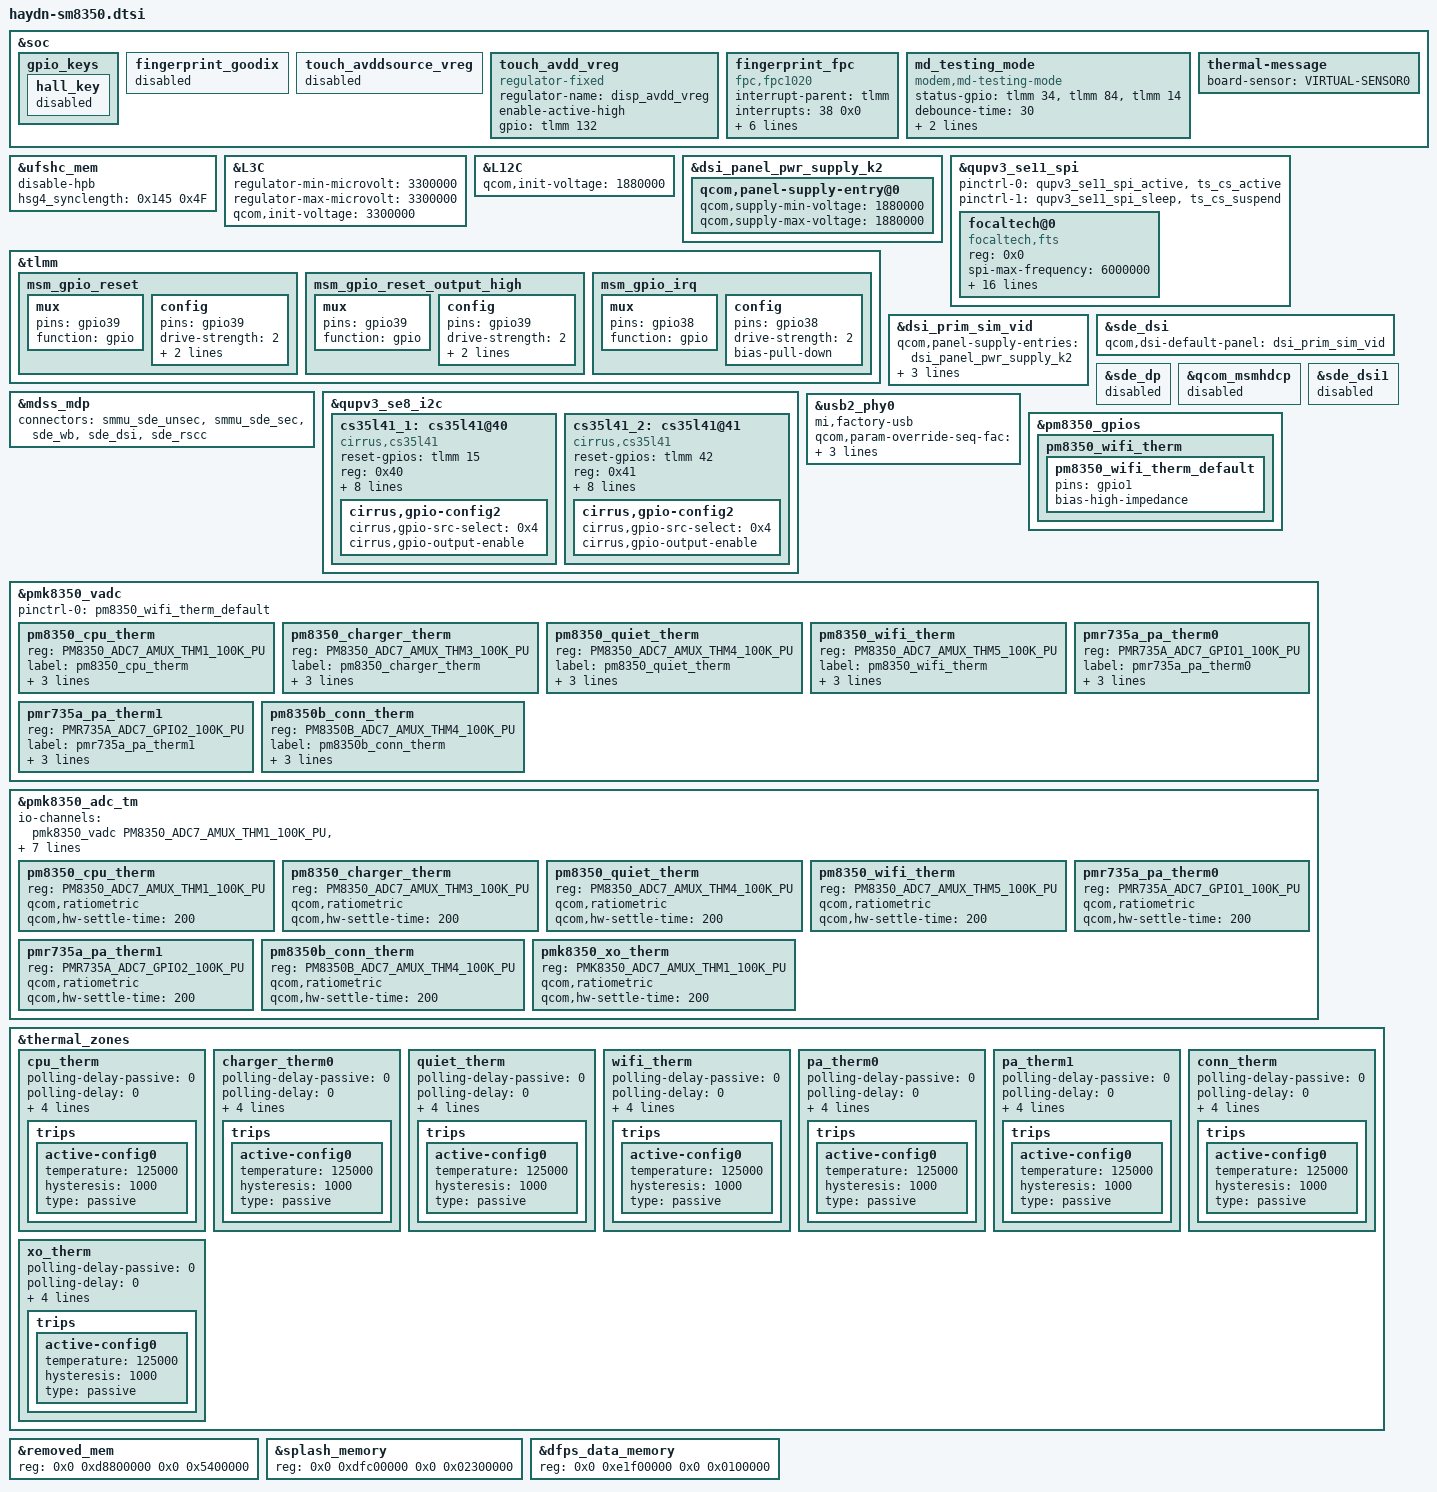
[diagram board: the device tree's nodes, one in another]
/*
this file is for attribution only of star
And public attribution of xiaomi platforms(like venus and so and)
*/

#include "haydn-pinctrl.dtsi"
#include "xiaomi-sm8350-common.dtsi"
#include "haydn-audio-overlay.dtsi"
#include "camera/haydn-sm8350-camera-sensor.dtsi"

&soc {
	gpio_keys {
		hall_key {
			status = "disable";
		};
	};
	fingerprint_goodix {
		status = "disable";
	};

	touch_avddsource_vreg {
		status = "disable";
	};

	touch_avdd_vreg: touch_avdd_vreg {
		compatible = "regulator-fixed";
		regulator-name = "disp_avdd_vreg";
		enable-active-high;
		gpio = <&tlmm 132 0>;
	};

	fingerprint_fpc {
		status = "ok";
		compatible = "fpc,fpc1020";
		interrupt-parent = <&tlmm>;
		interrupts = <38 0x0>;
		fpc,gpio_rst    = <&tlmm 39 0x0>;
		fpc,gpio_irq    = <&tlmm 38 0x0>;
		fp_vdd_vreg-supply = <&L3C>;
		pinctrl-names = "fpc1020_reset_reset",
						"fpc1020_reset_active",
						"fpc1020_irq_active";

		pinctrl-0 = <&msm_gpio_reset>;
		pinctrl-1 = <&msm_gpio_reset_output_high>;
		pinctrl-2 = <&msm_gpio_irq>;
	};

	md_testing_mode {
		compatible = "modem,md-testing-mode";
		status-gpio = <&tlmm 34 0x00>,
                      <&tlmm 84 0x00>,
					  <&tlmm 14 0x00>;
		debounce-time = <30>;
		pinctrl-names = "default";
		pinctrl-0 = <&ant1_ctrl_irq &ant3_ctrl_irq &ant8_ctrl_irq>;
	};
};

&ufshc_mem {
	disable-hpb;

	hsg4_synclength = /bits/ 16 <0x145 0x4F>;

	status = "ok";
};


&L3C {
	regulator-min-microvolt = <3300000>;
	regulator-max-microvolt = <3300000>;
	qcom,init-voltage = <3300000>;
};
&L12C {
	qcom,init-voltage = <1880000>;
};

&dsi_panel_pwr_supply_k2 {
	qcom,panel-supply-entry@0 {
		qcom,supply-min-voltage = <1880000>;
		qcom,supply-max-voltage = <1880000>;
	};
};

&tlmm {
		/* FP_RESET_N */
	msm_gpio_reset: msm_gpio_reset {
		mux {
			pins = "gpio39";
			function = "gpio";
		};
		config {
			pins = "gpio39";
			drive-strength = <2>;
			bias-disable;
			output-low;
		};
	};
		/* FP_RESET_N, state device active*/
	msm_gpio_reset_output_high: msm_gpio_reset_output_high {
		mux {
			pins = "gpio39";
			function = "gpio";
		};
		config {
			pins = "gpio39";
			drive-strength = <2>;
			bias-disable;
			output-high;
		};
	};
		/* FP_INT_N */
	msm_gpio_irq: msm_gpio_irq {
		mux {
			pins = "gpio38";
			function = "gpio";
		};
		config {
			pins = "gpio38";
			drive-strength = <2>;
			bias-pull-down;
		};
	};
};

&qupv3_se11_spi {
	status = "ok";
	pinctrl-0 = <&qupv3_se11_spi_active &ts_cs_active>;
	pinctrl-1 = <&qupv3_se11_spi_sleep &ts_cs_suspend>;
	focaltech@0 {
		status = "ok";
		compatible = "focaltech,fts";
		reg = <0x0>;
		spi-max-frequency = <6000000>;
		interrupt-parent = <&tlmm>;
		interrupts = <23 0x2008>;
		pinctrl-names = "pmx_ts_active", "pmx_ts_suspend", "pmx_ts_release";
		pinctrl-0 = <&mi_ts_active>;
		pinctrl-1 = <&ts_int_suspend &ts_reset_suspend>;
		pinctrl-2 = <&ts_release>;
		vdd-supply = <&touch_avdd_vreg>;
		vcc_i2c-supply = <&L2C>;
		focaltech,reset-gpio = <&tlmm 22 0x00>;
		focaltech,irq-gpio = <&tlmm 23 0x2008>;
		focaltech,max-touch-number = <10>;
		focaltech,display-coords = <0 0 8640 19200>;
		focaltech,open-min = <3000>;
		focaltech,touch-range-array = <1 5 10 15 20>;
		focaltech,touch-def-array = <3 3 3 3>;
		focaltech,touch-expert-array = <10 10 10 10
						20 20 15 10
						20 20 20 10>;
	};
};

&dsi_prim_sim_vid {
       qcom,panel-supply-entries = <&dsi_panel_pwr_supply_k2>;
       qcom,mdss-dsi-bl-pmic-control-type = "bl_ctrl_dcs";
       qcom,platform-reset-gpio = <&tlmm 24 0>;
};

&sde_dsi {
       qcom,dsi-default-panel = <&dsi_prim_sim_vid>;
};

&sde_dp {
	status = "disabled";
};

&qcom_msmhdcp {
	status = "disabled";
};

&sde_dsi1 {
	status = "disabled";
};

&mdss_mdp {
	connectors = <&smmu_sde_unsec &smmu_sde_sec &sde_wb &sde_dsi
		&sde_rscc>;
};

&qupv3_se8_i2c {
	status = "ok";
	cs35l41_1: cs35l41@40 {
		status = "ok";
		compatible = "cirrus,cs35l41";
		reset-gpios = <&tlmm 15 0>;
		reg = <0x40>;
		interrupt-parent = <&tlmm>;
		interrupts = <44 8>;
		cirrus,temp-warn_threshold = <3>;
		cirrus,boost-peak-milliamp = <4000>;
		cirrus,boost-ind-nanohenry = <1000>;
		cirrus,boost-cap-microfarad = <15>;
		cirrus,asp-sdout-hiz = <3>;
		sound-name-prefix = "RCV";
		cirrus,gpio-config2 {
			cirrus,gpio-src-select = <0x4>;
			cirrus,gpio-output-enable;
		};
	};
	cs35l41_2: cs35l41@41 {
		compatible = "cirrus,cs35l41";
		reset-gpios = <&tlmm 42 0>;
		reg = <0x41>;
		interrupt-parent = <&tlmm>;
		interrupts = <79 8>;
		cirrus,temp-warn_threshold = <3>;
		cirrus,boost-peak-milliamp = <4000>;
		cirrus,boost-ind-nanohenry = <1000>;
		cirrus,boost-cap-microfarad = <15>;
		cirrus,asp-sdout-hiz = <3>;
		cirrus,right-channel-amp;
		cirrus,gpio-config2 {
			cirrus,gpio-src-select = <0x4>;
			cirrus,gpio-output-enable;
		};
	};
};

&usb2_phy0 {
        mi,factory-usb;
        qcom,param-override-seq-fac =
        <0xc6 0x6c      /* override_x0 */
         0x0e 0x70      /* override_x1 */
         0x00 0x74>;    /* override x2 */
	qcom,param-override-seq =
        <0xc7 0x6c      /* override_x0 */
         0x0e 0x70      /* override_x1 */
         0x00 0x74>;    /* override x2 */
};

&pm8350_gpios {
	pm8350_wifi_therm {
		pm8350_wifi_therm_default: pm8350_wifi_therm_default {
			pins = "gpio1";
			bias-high-impedance;
		};
	};
};

&pmk8350_vadc {
	pinctrl-names = "default";
	pinctrl-0 = <&pm8350_wifi_therm_default>;

	pm8350_cpu_therm {
		reg = <PM8350_ADC7_AMUX_THM1_100K_PU>;
		label = "pm8350_cpu_therm";
		qcom,ratiometric;
		qcom,hw-settle-time = <200>;
		qcom,pre-scaling = <1 1>;
	};

	pm8350_charger_therm {
		reg = <PM8350_ADC7_AMUX_THM3_100K_PU>;
		label = "pm8350_charger_therm";
		qcom,ratiometric;
		qcom,hw-settle-time = <200>;
		qcom,pre-scaling = <1 1>;
	};

	pm8350_quiet_therm {
		reg = <PM8350_ADC7_AMUX_THM4_100K_PU>;
		label = "pm8350_quiet_therm";
		qcom,ratiometric;
		qcom,hw-settle-time = <200>;
		qcom,pre-scaling = <1 1>;
	};

	pm8350_wifi_therm {
		reg = <PM8350_ADC7_AMUX_THM5_100K_PU>;
		label = "pm8350_wifi_therm";
		qcom,ratiometric;
		qcom,hw-settle-time = <200>;
		qcom,pre-scaling = <1 1>;
	};

	pmr735a_pa_therm0 {
		reg = <PMR735A_ADC7_GPIO1_100K_PU>;
		label = "pmr735a_pa_therm0";
		qcom,ratiometric;
		qcom,hw-settle-time = <200>;
		qcom,pre-scaling = <1 1>;
	};

	pmr735a_pa_therm1 {
		reg = <PMR735A_ADC7_GPIO2_100K_PU>;
		label = "pmr735a_pa_therm1";
		qcom,ratiometric;
		qcom,hw-settle-time = <200>;
		qcom,pre-scaling = <1 1>;
	};

	pm8350b_conn_therm {
		reg = <PM8350B_ADC7_AMUX_THM4_100K_PU>;
		label = "pm8350b_conn_therm";
		qcom,ratiometric;
		qcom,hw-settle-time = <200>;
		qcom,pre-scaling = <1 1>;
	};
};

&pmk8350_adc_tm {
	io-channels = <&pmk8350_vadc PM8350_ADC7_AMUX_THM1_100K_PU>,	//cpu_therm
			<&pmk8350_vadc PM8350_ADC7_AMUX_THM3_100K_PU>,	//charger_therm0
			<&pmk8350_vadc PM8350_ADC7_AMUX_THM4_100K_PU>,	//quiet_therm
			<&pmk8350_vadc PM8350_ADC7_AMUX_THM5_100K_PU>,	//wifi_therm
			<&pmk8350_vadc PMR735A_ADC7_GPIO1_100K_PU>,	//pa_therm0
			<&pmk8350_vadc PMR735A_ADC7_GPIO2_100K_PU>,	//pa_therm1
			<&pmk8350_vadc PM8350B_ADC7_AMUX_THM4_100K_PU>,	//conn_therm
			<&pmk8350_vadc PMK8350_ADC7_AMUX_THM1_100K_PU>;	//xo_therm

	pm8350_cpu_therm {
		reg = <PM8350_ADC7_AMUX_THM1_100K_PU>;
		qcom,ratiometric;
		qcom,hw-settle-time = <200>;
	};

	pm8350_charger_therm {
		reg = <PM8350_ADC7_AMUX_THM3_100K_PU>;
		qcom,ratiometric;
		qcom,hw-settle-time = <200>;
	};

	pm8350_quiet_therm {
		reg = <PM8350_ADC7_AMUX_THM4_100K_PU>;
		qcom,ratiometric;
		qcom,hw-settle-time = <200>;
	};

	pm8350_wifi_therm {
		reg = <PM8350_ADC7_AMUX_THM5_100K_PU>;
		qcom,ratiometric;
		qcom,hw-settle-time = <200>;
	};

	pmr735a_pa_therm0 {
		reg = <PMR735A_ADC7_GPIO1_100K_PU>;
		qcom,ratiometric;
		qcom,hw-settle-time = <200>;
	};

	pmr735a_pa_therm1 {
		reg = <PMR735A_ADC7_GPIO2_100K_PU>;
		qcom,ratiometric;
		qcom,hw-settle-time = <200>;
	};

	pm8350b_conn_therm {
		reg = <PM8350B_ADC7_AMUX_THM4_100K_PU>;
		qcom,ratiometric;
		qcom,hw-settle-time = <200>;
	};

	pmk8350_xo_therm {
		reg = <PMK8350_ADC7_AMUX_THM1_100K_PU>;
		qcom,ratiometric;
		qcom,hw-settle-time = <200>;
	};
};

&thermal_zones {
        cpu_therm {
                polling-delay-passive = <0>;
                polling-delay = <0>;
                thermal-governor = "user_space";
                thermal-sensors = <&pmk8350_adc_tm PM8350_ADC7_AMUX_THM1_100K_PU>;
                wake-capable-sensor;
                trips {
                        active-config0 {
                                temperature = <125000>;
                                hysteresis = <1000>;
                                type = "passive";
                        };
                };
        };

        charger_therm0 {
                polling-delay-passive = <0>;
                polling-delay = <0>;
                thermal-governor = "user_space";
                thermal-sensors = <&pmk8350_adc_tm PM8350_ADC7_AMUX_THM3_100K_PU>;
                wake-capable-sensor;
                trips {
                        active-config0 {
                                temperature = <125000>;
                                hysteresis = <1000>;
                                type = "passive";
                        };
                };
        };

        quiet_therm {
                polling-delay-passive = <0>;
                polling-delay = <0>;
                thermal-governor = "user_space";
                thermal-sensors = <&pmk8350_adc_tm PM8350_ADC7_AMUX_THM4_100K_PU>;
                wake-capable-sensor;
                trips {
                        active-config0 {
                                temperature = <125000>;
                                hysteresis = <1000>;
                                type = "passive";
                        };
                };
        };

        wifi_therm {
                polling-delay-passive = <0>;
                polling-delay = <0>;
                thermal-governor = "user_space";
                thermal-sensors = <&pmk8350_adc_tm PM8350_ADC7_AMUX_THM5_100K_PU>;
                wake-capable-sensor;
                trips {
                        active-config0 {
                                temperature = <125000>;
                                hysteresis = <1000>;
                                type = "passive";
                        };
                };
        };

        pa_therm0 {
                polling-delay-passive = <0>;
                polling-delay = <0>;
                thermal-governor = "user_space";
                thermal-sensors = <&pmk8350_adc_tm PMR735A_ADC7_GPIO1_100K_PU>;
                wake-capable-sensor;
                trips {
                        active-config0 {
                                temperature = <125000>;
                                hysteresis = <1000>;
                                type = "passive";
                        };
                };
        };

        pa_therm1 {
                polling-delay-passive = <0>;
                polling-delay = <0>;
                thermal-governor = "user_space";
                thermal-sensors = <&pmk8350_adc_tm PMR735A_ADC7_GPIO2_100K_PU>;
                wake-capable-sensor;
                trips {
                        active-config0 {
                                temperature = <125000>;
                                hysteresis = <1000>;
                                type = "passive";
                        };
                };
        };

	conn_therm {
		polling-delay-passive = <0>;
		polling-delay = <0>;
		thermal-governor = "user_space";
		thermal-sensors = <&pmk8350_adc_tm PM8350B_ADC7_AMUX_THM4_100K_PU>;
		wake-capable-sensor;
		trips {
			active-config0 {
				temperature = <125000>;
				hysteresis = <1000>;
				type = "passive";
			};
		};
	};

	xo_therm {
		polling-delay-passive = <0>;
		polling-delay = <0>;
		thermal-governor = "user_space";
		thermal-sensors = <&pmk8350_adc_tm PMK8350_ADC7_AMUX_THM1_100K_PU>;
		wake-capable-sensor;
		trips {
			active-config0 {
				temperature = <125000>;
				hysteresis = <1000>;
				type = "passive";
			};
		};
	};
};

&soc {
	thermal-message {
		board-sensor = "VIRTUAL-SENSOR0";
	};
};

&removed_mem {
	reg = <0x0 0xd8800000 0x0 0x5400000>;
};

&splash_memory {
	reg = <0x0 0xdfc00000 0x0 0x02300000>;
};

&dfps_data_memory {
	reg = <0x0 0xe1f00000 0x0 0x0100000>;
};
